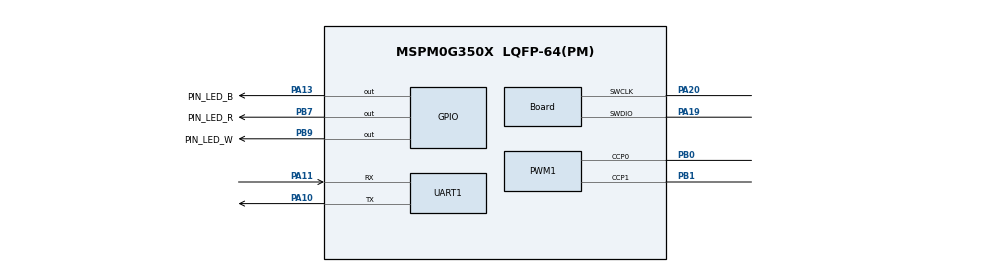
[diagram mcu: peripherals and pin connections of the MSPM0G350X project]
/**
 * @cliArgs --device "MSPM0G350X" --part "Default" --package "LQFP-64(PM)" --product "mspm0_sdk@2.05.01.01"
 * @versions {"tool":"1.24.0+4110"}
 */

/**
 * Import the modules used in this configuration.
 */
const GPIO   = scripting.addModule("/ti/driverlib/GPIO", {}, false);
const GPIO1  = GPIO.addInstance();
const GPIO2  = GPIO.addInstance();
const PWM    = scripting.addModule("/ti/driverlib/PWM", {}, false);
const PWM1   = PWM.addInstance();
const SYSCTL = scripting.addModule("/ti/driverlib/SYSCTL");
const TIMER  = scripting.addModule("/ti/driverlib/TIMER", {}, false);
const TIMER1 = TIMER.addInstance();
const UART   = scripting.addModule("/ti/driverlib/UART", {}, false);
const UART1  = UART.addInstance();
const UART2  = UART.addInstance();
const UART3  = UART.addInstance();

/**
 * Write custom configuration values to the imported modules.
 */
GPIO1.$name                              = "GPIO_LED";
GPIO1.associatedPins.create(4);
GPIO1.associatedPins[0].$name            = "PIN_LED_R";
GPIO1.associatedPins[0].internalResistor = "PULL_DOWN";
GPIO1.associatedPins[0].assignedPort     = "PORTB";
GPIO1.associatedPins[0].assignedPin      = "7";
GPIO1.associatedPins[0].pin.$assign      = "PB7";
GPIO1.associatedPins[1].$name            = "PIN_LED_W";
GPIO1.associatedPins[1].internalResistor = "PULL_DOWN";
GPIO1.associatedPins[1].assignedPort     = "PORTB";
GPIO1.associatedPins[1].assignedPin      = "9";
GPIO1.associatedPins[1].pin.$assign      = "PB9";
GPIO1.associatedPins[2].$name            = "PIN_LED_B";
GPIO1.associatedPins[2].assignedPort     = "PORTA";
GPIO1.associatedPins[2].internalResistor = "PULL_DOWN";
GPIO1.associatedPins[2].assignedPin      = "13";
GPIO1.associatedPins[2].pin.$assign      = "PA13";
GPIO1.associatedPins[3].$name            = "PIN_LED_G";
GPIO1.associatedPins[3].internalResistor = "PULL_DOWN";
GPIO1.associatedPins[3].assignedPort     = "PORTB";
GPIO1.associatedPins[3].assignedPin      = "26";

const Board                       = scripting.addModule("/ti/driverlib/Board", {}, false);
Board.peripheral.$assign          = "DEBUGSS";
Board.peripheral.swclkPin.$assign = "PA20";
Board.peripheral.swdioPin.$assign = "PA19";

GPIO2.$name                               = "GPIO_KEY";
GPIO2.port                                = "PORTA";
GPIO2.associatedPins.create(4);
GPIO2.associatedPins[0].$name             = "PIN_KEY1";
GPIO2.associatedPins[0].internalResistor  = "PULL_UP";
GPIO2.associatedPins[0].assignedPin       = "28";
GPIO2.associatedPins[0].interruptEn       = true;
GPIO2.associatedPins[0].interruptPriority = "1";
GPIO2.associatedPins[0].polarity          = "FALL";
GPIO2.associatedPins[0].direction         = "INPUT";
GPIO2.associatedPins[1].$name             = "PIN_KEY2";
GPIO2.associatedPins[1].direction         = "INPUT";
GPIO2.associatedPins[1].assignedPin       = "29";
GPIO2.associatedPins[1].internalResistor  = "PULL_UP";
GPIO2.associatedPins[1].interruptEn       = true;
GPIO2.associatedPins[1].interruptPriority = "1";
GPIO2.associatedPins[1].polarity          = "FALL";
GPIO2.associatedPins[2].$name             = "PIN_KEY3";
GPIO2.associatedPins[2].direction         = "INPUT";
GPIO2.associatedPins[2].assignedPin       = "30";
GPIO2.associatedPins[2].interruptEn       = true;
GPIO2.associatedPins[2].interruptPriority = "1";
GPIO2.associatedPins[2].polarity          = "FALL";
GPIO2.associatedPins[2].internalResistor  = "PULL_DOWN";
GPIO2.associatedPins[3].$name             = "PIN_KEY4";
GPIO2.associatedPins[3].direction         = "INPUT";
GPIO2.associatedPins[3].assignedPin       = "31";
GPIO2.associatedPins[3].polarity          = "FALL";
GPIO2.associatedPins[3].interruptPriority = "1";
GPIO2.associatedPins[3].internalResistor  = "PULL_DOWN";

PWM1.$name                              = "PWM_SERVO";
PWM1.clockDivider                       = 8;
PWM1.timerStartTimer                    = true;
PWM1.clockPrescale                      = 100;
PWM1.timerCount                         = 800;
PWM1.pwmMode                            = "EDGE_ALIGN_UP";
PWM1.peripheral.$assign                 = "TIMA1";
PWM1.peripheral.ccp0Pin.$assign         = "PB0";
PWM1.peripheral.ccp1Pin.$assign         = "PB1";
PWM1.PWM_CHANNEL_0.$name                = "ti_driverlib_pwm_PWMTimerCC2";
PWM1.PWM_CHANNEL_1.$name                = "ti_driverlib_pwm_PWMTimerCC3";
PWM1.ccp0PinConfig.direction            = scripting.forceWrite("OUTPUT");
PWM1.ccp0PinConfig.hideOutputInversion  = scripting.forceWrite(false);
PWM1.ccp0PinConfig.onlyInternalResistor = scripting.forceWrite(false);
PWM1.ccp0PinConfig.passedPeripheralType = scripting.forceWrite("Digital");
PWM1.ccp0PinConfig.$name                = "ti_driverlib_gpio_GPIOPinGeneric6";
PWM1.ccp1PinConfig.direction            = scripting.forceWrite("OUTPUT");
PWM1.ccp1PinConfig.hideOutputInversion  = scripting.forceWrite(false);
PWM1.ccp1PinConfig.onlyInternalResistor = scripting.forceWrite(false);
PWM1.ccp1PinConfig.passedPeripheralType = scripting.forceWrite("Digital");
PWM1.ccp1PinConfig.$name                = "ti_driverlib_gpio_GPIOPinGeneric7";

SYSCTL.forceDefaultClkConfig = true;
SYSCTL.peripheral.$assign    = "SYSCTL";

TIMER1.$name             = "CLOCK";
TIMER1.timerStartTimer   = true;
TIMER1.interrupts        = ["REPC"];
TIMER1.interruptPriority = "1";
TIMER1.timerMode         = "PERIODIC";
TIMER1.timerClkDiv       = 8;
TIMER1.repeatCounter     = 4;
TIMER1.timerPeriod       = "5 ms";
TIMER1.timerClkPrescale  = 4;

UART1.$name                    = "UART_0";
UART1.targetBaudRate           = 115200;
UART1.enabledInterrupts        = ["RX"];
UART1.interruptPriority        = "1";
UART1.peripheral.$assign       = "UART0";
UART1.peripheral.rxPin.$assign = "PA11";
UART1.peripheral.txPin.$assign = "PA10";
UART1.txPinConfig.$name        = "ti_driverlib_gpio_GPIOPinGeneric8";
UART1.rxPinConfig.$name        = "ti_driverlib_gpio_GPIOPinGeneric9";

UART2.$name              = "UART_1";
UART2.targetBaudRate     = 115200;
UART2.enabledInterrupts  = ["RX"];
UART2.interruptPriority  = "1";
UART2.peripheral.$assign = "UART2";
UART2.txPinConfig.$name  = "ti_driverlib_gpio_GPIOPinGeneric10";
UART2.rxPinConfig.$name  = "ti_driverlib_gpio_GPIOPinGeneric11";

UART3.$name             = "UART_2";
UART3.targetBaudRate    = 115200;
UART3.enabledInterrupts = ["RX"];
UART3.interruptPriority = "1";
UART3.txPinConfig.$name = "ti_driverlib_gpio_GPIOPinGeneric12";
UART3.rxPinConfig.$name = "ti_driverlib_gpio_GPIOPinGeneric13";

const ProjectConfig              = scripting.addModule("/ti/project_config/ProjectConfig", {}, false);
ProjectConfig.migrationCondition = true;

/**
 * Pinmux solution for unlocked pins/peripherals. This ensures that minor changes to the automatic solver in a future
 * version of the tool will not impact the pinmux you originally saw.  These lines can be completely deleted in order to
 * re-solve from scratch.
 */
GPIO1.associatedPins[3].pin.$suggestSolution = "PB26";
GPIO2.associatedPins[0].pin.$suggestSolution = "PA28";
GPIO2.associatedPins[1].pin.$suggestSolution = "PA29";
GPIO2.associatedPins[2].pin.$suggestSolution = "PA30";
GPIO2.associatedPins[3].pin.$suggestSolution = "PA31";
TIMER1.peripheral.$suggestSolution           = "TIMA0";
UART2.peripheral.rxPin.$suggestSolution      = "PA22";
UART2.peripheral.txPin.$suggestSolution      = "PA21";
UART3.peripheral.$suggestSolution            = "UART1";
UART3.peripheral.rxPin.$suggestSolution      = "PA18";
UART3.peripheral.txPin.$suggestSolution      = "PA17";
